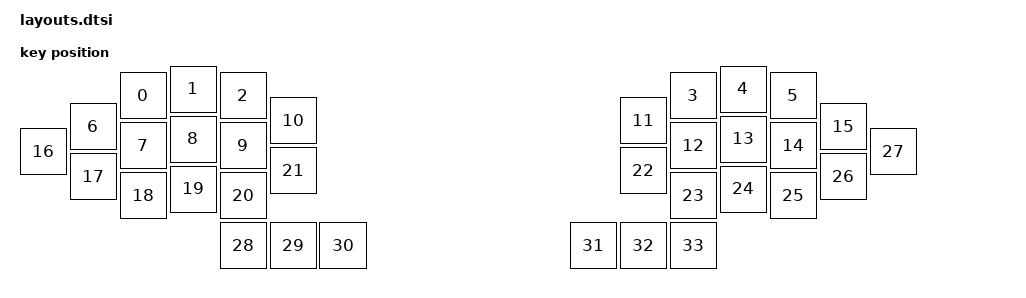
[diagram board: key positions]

#include <physical_layouts.dtsi>
/ {
    physical_layout0: physical_layout0 {
        compatible = "zmk,physical-layout";
        display-name = "Layout";
        keys
            = <&key_physical_attrs 100 100 450 63 0 0 0>
			,<&key_physical_attrs 100 100 550 50 0 0 0>
			,<&key_physical_attrs 100 100 650 63 0 0 0>
			,<&key_physical_attrs 100 100 1550 63 0 0 0>
			,<&key_physical_attrs 100 100 1650 50 0 0 0>
			,<&key_physical_attrs 100 100 1750 63 0 0 0>
			,<&key_physical_attrs 100 100 350 125 0 0 0>
			,<&key_physical_attrs 100 100 450 163 0 0 0>
			,<&key_physical_attrs 100 100 550 150 0 0 0>
			,<&key_physical_attrs 100 100 650 163 0 0 0>
			,<&key_physical_attrs 100 100 750 113 0 0 0>
			,<&key_physical_attrs 100 100 1450 113 0 0 0>
			,<&key_physical_attrs 100 100 1550 163 0 0 0>
			,<&key_physical_attrs 100 100 1650 150 0 0 0>
			,<&key_physical_attrs 100 100 1750 163 0 0 0>
			,<&key_physical_attrs 100 100 1850 125 0 0 0>
			,<&key_physical_attrs 100 100 250 175 0 0 0>
			,<&key_physical_attrs 100 100 350 225 0 0 0>
			,<&key_physical_attrs 100 100 450 263 0 0 0>
			,<&key_physical_attrs 100 100 550 250 0 0 0>
			,<&key_physical_attrs 100 100 650 263 0 0 0>
			,<&key_physical_attrs 100 100 750 213 0 0 0>
			,<&key_physical_attrs 100 100 1450 213 0 0 0>
			,<&key_physical_attrs 100 100 1550 263 0 0 0>
			,<&key_physical_attrs 100 100 1650 250 0 0 0>
			,<&key_physical_attrs 100 100 1750 263 0 0 0>
			,<&key_physical_attrs 100 100 1850 225 0 0 0>
			,<&key_physical_attrs 100 100 1950 175 0 0 0>
			,<&key_physical_attrs 100 100 650 363 0 0 0>
			,<&key_physical_attrs 100 100 750 363 0 0 0>
			,<&key_physical_attrs 100 100 850 363 0 0 0>
			,<&key_physical_attrs 100 100 1350 363 0 0 0>
			,<&key_physical_attrs 100 100 1450 363 0 0 0>
			,<&key_physical_attrs 100 100 1550 363 0 0 0>
            ;
    };
};
    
